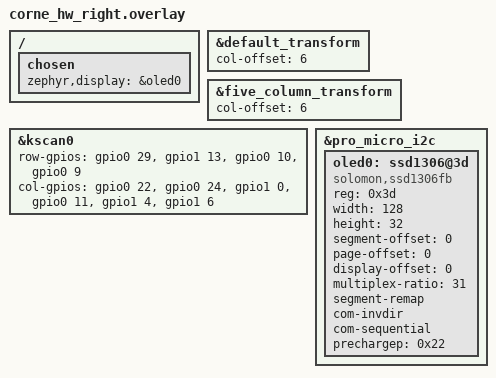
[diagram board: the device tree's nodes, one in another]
/*
 * Copyright (c) 2020 The ZMK Contributors
 *
 * SPDX-License-Identifier: MIT
 */

#include <dt-bindings/pinctrl/nrf-pinctrl.h>
#include <dt-bindings/i2c/i2c.h>
#include "corne_hw.dtsi"

&default_transform {
    col-offset = <6>;
};

&five_column_transform {
    col-offset = <6>;
};

&kscan0 {
  

    row-gpios = <&gpio0 29  (GPIO_ACTIVE_HIGH | GPIO_PULL_DOWN)>,
                    <&gpio1 13 (GPIO_ACTIVE_HIGH | GPIO_PULL_DOWN)>,
                    <&gpio0 10  (GPIO_ACTIVE_HIGH | GPIO_PULL_DOWN)>,
                    <&gpio0 9  (GPIO_ACTIVE_HIGH | GPIO_PULL_DOWN)>;

   
        col-gpios = <&gpio0 22 GPIO_ACTIVE_HIGH>,
                    <&gpio0 24 GPIO_ACTIVE_HIGH>,
                    <&gpio1 0  GPIO_ACTIVE_HIGH>,
                    <&gpio0 11 GPIO_ACTIVE_HIGH>,
                    <&gpio1 4  GPIO_ACTIVE_HIGH>,
                    <&gpio1 6  GPIO_ACTIVE_HIGH>;
};

/ {
    chosen {
        zephyr,display = &oled0;
    };
};

// OLED configuration - using pro_micro_i2c on Nice Nano (same as working left side)
// Pins: SDA=P0.17, SCL=P0.20 (board defaults)
&pro_micro_i2c {
    status = "okay";

    oled0: ssd1306@3d {
        compatible = "solomon,ssd1306fb";
        reg = <0x3d>;
        width = <128>;
        height = <32>;
        segment-offset = <0>;
        page-offset = <0>;
        display-offset = <0>;
        multiplex-ratio = <31>;
        segment-remap;
        com-invdir;
        com-sequential;
        prechargep = <0x22>;
    };
};

// pinctrl configuration is handled by the board (Nice Nano)

